AUTOSAR XML (schema 00046)
# Copyright 2015-2016 The MathWorks, Inc.
package /pkg/tst002
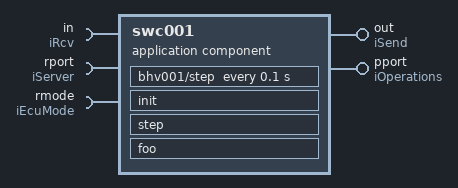
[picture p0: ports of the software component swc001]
  application sw component type swc001
    require port in: required-interface=iRcv
      required-com-specs:
        {data-element=e1, alive-timeout=60.0, init-value=constant-reference={short-label=DefaultInitValue_e1, constant=C42}}
        {data-element=e2, alive-timeout=60.0, init-value=constant-reference={short-label=DefaultInitValu_76a35ae5448e6270, constant=C0p89}}
        {data-element=e3, alive-timeout=60.0, init-value=constant-reference={short-label=init, constant=ZERO}}
        {data-element=e4, alive-timeout=60.0, init-value=constant-reference={short-label=DefaultInitValu_0147db48be8e2d8b, constant=CInit_array2}}
        {data-element=e5, alive-timeout=60.0, init-value=constant-reference={short-label=DefaultInitValue_struc001, constant=CInit_struc001}}
        {data-element=e6, alive-timeout=60.0, init-value=constant-reference={short-label=DefaultInitValue_Enum001, constant=RED}}
    provide port out: provided-interface=iSend
    provide port pport: provided-interface=iOperations
    require port rport: required-interface=iServer
    require port rmode: required-interface=iEcuMode
    behavior bhv001: data-type-mapping=pkgDataTypeMappingsSet, handle-termination-and-restart=NO-SUPPORT, supports-multiple-instantiation=true
      timing event onesec: start-on-event=bhv001/step, period=0.1
      operation invoked event call_foo: start-on-event=foo, operation=pport.foo
      swc mode switch event on_init: start-on-event=init, activation=ON-ENTRY, mode=rmode.currentMode.Init
      per instance memory pim_one: type=Int_n320to320, type-definition=/pkg/types/app/Int_n320to320
      runnable init
      runnable step
        data-read-access:
          6 x access:
            IN_input_e{1..6}: accessed-variable=in.e{1..6}
        data-write-access:
          6 x access:
            OUT_output_e{1..6}: accessed-variable=out.e{1..6}
      runnable foo: minimum-start-interval=1.0, can-be-invoked-concurrently=true
        async call asyncCallBar: category=GENERAL, operation=rport.bar, timeout=0.1
  application sw component type swc002
    behavior bhv: supports-multiple-instantiation=true
      timing event twosec: start-on-event=bhv/step, period=0.2
      runnable step
